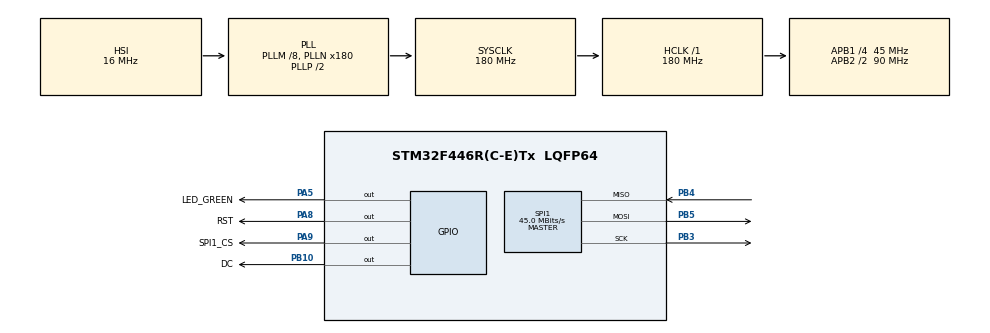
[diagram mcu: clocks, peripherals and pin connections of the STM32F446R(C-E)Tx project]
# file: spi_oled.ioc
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Mcu.Family=STM32F4
Mcu.Name=STM32F446R(C-E)Tx
Mcu.Package=LQFP64
NVIC.PriorityGroup=NVIC_PRIORITYGROUP_4
PA5.GPIO_Label=LED_GREEN
PA5.Signal=GPIO_Output
PA8.GPIO_Label=RST
PA8.Signal=GPIO_Output
PA9.GPIO_Label=SPI1_CS
PA9.Signal=GPIO_Output
PB10.GPIO_Label=DC
PB10.Signal=GPIO_Output
PB3.Mode=Full_Duplex_Master
PB3.Signal=SPI1_SCK
PB4.Mode=Full_Duplex_Master
PB4.Signal=SPI1_MISO
PB5.Mode=Full_Duplex_Master
PB5.Signal=SPI1_MOSI
ProjectManager.HeapSize=0x200
ProjectManager.StackSize=0x400
ProjectManager.TargetToolchain=MDK-ARM V5.27
RCC.AHBFreq_Value=180000000
RCC.APB1CLKDivider=RCC_HCLK_DIV4
RCC.APB1Freq_Value=45000000
RCC.APB1TimFreq_Value=90000000
RCC.APB2CLKDivider=RCC_HCLK_DIV2
RCC.APB2Freq_Value=90000000
RCC.APB2TimFreq_Value=180000000
RCC.CortexFreq_Value=180000000
RCC.HCLKFreq_Value=180000000
RCC.PLLM=8
RCC.PLLN=180
RCC.SYSCLKFreq_VALUE=180000000
RCC.SYSCLKSource=RCC_SYSCLKSOURCE_PLLCLK
RCC.USBFreq_Value=180000000
RCC.VCOOutputFreq_Value=360000000
SPI1.CalculateBaudRate=45.0 MBits/s
SPI1.Direction=SPI_DIRECTION_2LINES
SPI1.Mode=SPI_MODE_MASTER
SPI1.VirtualType=VM_MASTER
board=custom

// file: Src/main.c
/* USER CODE BEGIN Header */
/**
  ******************************************************************************
  * @file           : main.c
  * @brief          : Main program body
  ******************************************************************************
  * @attention
  *
  * <h2><center>&copy; Copyright (c) 2020 STMicroelectronics.
  * All rights reserved.</center></h2>
  *
  * This software component is licensed by ST under BSD 3-Clause license,
  * the "License"; You may not use this file except in compliance with the
  * License. You may obtain a copy of the License at:
  *                        opensource.org/licenses/BSD-3-Clause
  *
  ******************************************************************************
  */
/* USER CODE END Header */

#include "main.h"

/* USER CODE BEGIN Includes */
#include "display_manager.h"
/* USER CODE END Includes */

SPI_HandleTypeDef hspi1;

void SystemClock_Config(void);
static void MX_GPIO_Init(void);
static void MX_SPI1_Init(void);

int main(void)
{

  /* MCU Configuration--------------------------------------------------------*/

  /* Reset of all peripherals, Initializes the Flash interface and the Systick. */
  HAL_Init();

  /* Configure the system clock */
  SystemClock_Config();

  /* Initialize all configured peripherals */
  MX_GPIO_Init();
  MX_SPI1_Init();
  /* USER CODE BEGIN 2 */
	// Initialize display
	display_init();
	// Clear
	display_clear();
	uint32_t count = 1;
	/* USER CODE END 2 */

  /* Infinite loop */
  while (1)
  {

    /* USER CODE BEGIN 3 */
		display_test_step_sequencer(count);
		count++;
	}
  /* USER CODE END 3 */
}

void SystemClock_Config(void)
{
  RCC_OscInitTypeDef RCC_OscInitStruct = {0};
  RCC_ClkInitTypeDef RCC_ClkInitStruct = {0};

  /** Configure the main internal regulator output voltage
  */
  __HAL_RCC_PWR_CLK_ENABLE();
  __HAL_PWR_VOLTAGESCALING_CONFIG(PWR_REGULATOR_VOLTAGE_SCALE1);
  /** Initializes the CPU, AHB and APB busses clocks
  */
  RCC_OscInitStruct.OscillatorType = RCC_OSCILLATORTYPE_HSI;
  RCC_OscInitStruct.HSIState = RCC_HSI_ON;
  RCC_OscInitStruct.HSICalibrationValue = RCC_HSICALIBRATION_DEFAULT;
  RCC_OscInitStruct.PLL.PLLState = RCC_PLL_ON;
  RCC_OscInitStruct.PLL.PLLSource = RCC_PLLSOURCE_HSI;
  RCC_OscInitStruct.PLL.PLLM = 8;
  RCC_OscInitStruct.PLL.PLLN = 180;
  RCC_OscInitStruct.PLL.PLLP = RCC_PLLP_DIV2;
  RCC_OscInitStruct.PLL.PLLQ = 2;
  RCC_OscInitStruct.PLL.PLLR = 2;
  if (HAL_RCC_OscConfig(&RCC_OscInitStruct) != HAL_OK)
  {
    Error_Handler();
  }
  /** Activate the Over-Drive mode
  */
  if (HAL_PWREx_EnableOverDrive() != HAL_OK)
  {
    Error_Handler();
  }
  /** Initializes the CPU, AHB and APB busses clocks
  */
  RCC_ClkInitStruct.ClockType = RCC_CLOCKTYPE_HCLK|RCC_CLOCKTYPE_SYSCLK
                              |RCC_CLOCKTYPE_PCLK1|RCC_CLOCKTYPE_PCLK2;
  RCC_ClkInitStruct.SYSCLKSource = RCC_SYSCLKSOURCE_PLLCLK;
  RCC_ClkInitStruct.AHBCLKDivider = RCC_SYSCLK_DIV1;
  RCC_ClkInitStruct.APB1CLKDivider = RCC_HCLK_DIV4;
  RCC_ClkInitStruct.APB2CLKDivider = RCC_HCLK_DIV2;

  if (HAL_RCC_ClockConfig(&RCC_ClkInitStruct, FLASH_LATENCY_5) != HAL_OK)
  {
    Error_Handler();
  }
}

static void MX_SPI1_Init(void)
{

  /* SPI1 parameter configuration*/
  hspi1.Instance = SPI1;
  hspi1.Init.Mode = SPI_MODE_MASTER;
  hspi1.Init.Direction = SPI_DIRECTION_2LINES;
  hspi1.Init.DataSize = SPI_DATASIZE_8BIT;
  hspi1.Init.CLKPolarity = SPI_POLARITY_LOW;
  hspi1.Init.CLKPhase = SPI_PHASE_1EDGE;
  hspi1.Init.NSS = SPI_NSS_SOFT;
  hspi1.Init.BaudRatePrescaler = SPI_BAUDRATEPRESCALER_2;
  hspi1.Init.FirstBit = SPI_FIRSTBIT_MSB;
  hspi1.Init.TIMode = SPI_TIMODE_DISABLE;
  hspi1.Init.CRCCalculation = SPI_CRCCALCULATION_DISABLE;
  hspi1.Init.CRCPolynomial = 10;
  if (HAL_SPI_Init(&hspi1) != HAL_OK)
  {
    Error_Handler();
  }

}

static void MX_GPIO_Init(void)
{
  GPIO_InitTypeDef GPIO_InitStruct = {0};

  /* GPIO Ports Clock Enable */
  __HAL_RCC_GPIOA_CLK_ENABLE();
  __HAL_RCC_GPIOB_CLK_ENABLE();

  /*Configure GPIO pin Output Level */
  HAL_GPIO_WritePin(GPIOA, LED_GREEN_Pin|RST_Pin|SPI1_CS_Pin, GPIO_PIN_RESET);

  /*Configure GPIO pin Output Level */
  HAL_GPIO_WritePin(DC_GPIO_Port, DC_Pin, GPIO_PIN_RESET);

  /*Configure GPIO pins : LED_GREEN_Pin RST_Pin SPI1_CS_Pin */
  GPIO_InitStruct.Pin = LED_GREEN_Pin|RST_Pin|SPI1_CS_Pin;
  GPIO_InitStruct.Mode = GPIO_MODE_OUTPUT_PP;
  GPIO_InitStruct.Pull = GPIO_NOPULL;
  GPIO_InitStruct.Speed = GPIO_SPEED_FREQ_LOW;
  HAL_GPIO_Init(GPIOA, &GPIO_InitStruct);

  /*Configure GPIO pin : DC_Pin */
  GPIO_InitStruct.Pin = DC_Pin;
  GPIO_InitStruct.Mode = GPIO_MODE_OUTPUT_PP;
  GPIO_InitStruct.Pull = GPIO_NOPULL;
  GPIO_InitStruct.Speed = GPIO_SPEED_FREQ_LOW;
  HAL_GPIO_Init(DC_GPIO_Port, &GPIO_InitStruct);

}

void Error_Handler(void)
{
}

/************************ (C) COPYRIGHT STMicroelectronics *****END OF FILE****/
